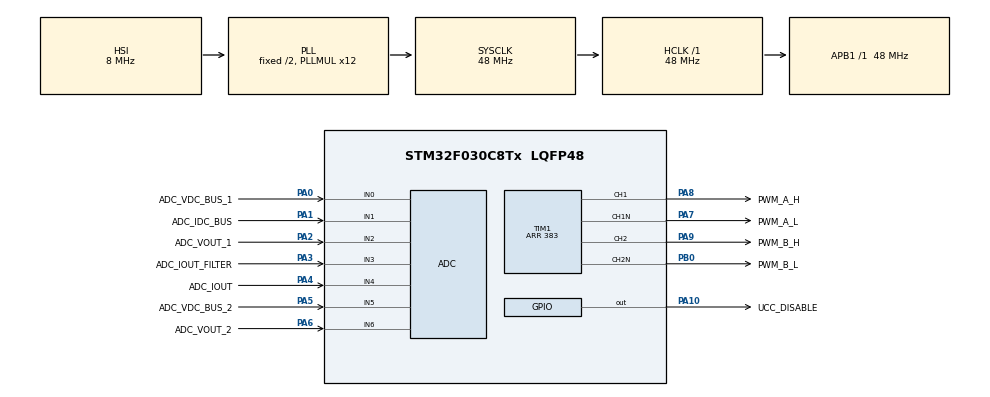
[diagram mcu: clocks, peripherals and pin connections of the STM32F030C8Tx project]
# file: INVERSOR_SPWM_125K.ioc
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ADC.SamplingTime=ADC_SAMPLETIME_28CYCLES_5
Mcu.Family=STM32F0
Mcu.Name=STM32F030C8Tx
Mcu.Package=LQFP48
NVIC.TIM1_BRK_UP_TRG_COM_IRQn=true\:0\:0\:false\:false\:true\:true\:true\:true
PA0.GPIO_Label=ADC_VDC_BUS_1
PA0.Mode=IN0
PA0.Signal=ADC_IN0
PA1.GPIO_Label=ADC_IDC_BUS 
PA1.Mode=IN1
PA1.Signal=ADC_IN1
PA10.GPIO_Label=UCC_DISABLE
PA10.GPIO_ModeDefaultOutputPP=GPIO_MODE_OUTPUT_PP
PA10.GPIO_PuPd=GPIO_NOPULL
PA10.PinState=GPIO_PIN_SET
PA10.Signal=GPIO_Output
PA13.Mode=Serial_Wire
PA13.Signal=SYS_SWDIO
PA14.Mode=Serial_Wire
PA14.Signal=SYS_SWCLK
PA2.GPIO_Label=ADC_VOUT_1
PA2.Mode=IN2
PA2.Signal=ADC_IN2
PA3.GPIO_Label=ADC_IOUT_FILTER
PA3.Mode=IN3
PA3.Signal=ADC_IN3
PA4.GPIO_Label=ADC_IOUT
PA4.Mode=IN4
PA4.Signal=ADC_IN4
PA5.GPIO_Label=ADC_VDC_BUS_2
PA5.Mode=IN5
PA5.Signal=ADC_IN5
PA6.GPIO_Label=ADC_VOUT_2
PA6.Mode=IN6
PA6.Signal=ADC_IN6
PA7.GPIO_Label=PWM_A_L
PA7.GPIO_Speed=GPIO_SPEED_FREQ_HIGH
PA7.Mode=PWM Generation1 CH1 CH1N
PA7.Signal=TIM1_CH1N
PA8.GPIO_Label=PWM_A_H
PA8.GPIO_Speed=GPIO_SPEED_FREQ_HIGH
PA8.Signal=S_TIM1_CH1
PA9.GPIO_Label=PWM_B_H
PA9.GPIO_Speed=GPIO_SPEED_FREQ_HIGH
PA9.Signal=S_TIM1_CH2
PB0.GPIO_Label=PWM_B_L
PB0.GPIO_Speed=GPIO_SPEED_FREQ_HIGH
PB0.Mode=PWM Generation2 CH2 CH2N
PB0.Signal=TIM1_CH2N
ProjectManager.HeapSize=0x200
ProjectManager.StackSize=0x400
ProjectManager.TargetToolchain=CMake
RCC.AHBFreq_Value=48000000
RCC.APB1Freq_Value=48000000
RCC.APB1TimFreq_Value=48000000
RCC.HCLKFreq_Value=48000000
RCC.PLLMUL=RCC_PLL_MUL12
RCC.SYSCLKFreq_VALUE=48000000
RCC.SYSCLKSource=RCC_SYSCLKSOURCE_PLLCLK
SH.S_TIM1_CH1.0=TIM1_CH1,PWM Generation1 CH1 CH1N
SH.S_TIM1_CH2.0=TIM1_CH2,PWM Generation2 CH2 CH2N
TIM1.AutoReloadPreload=TIM_AUTORELOAD_PRELOAD_ENABLE
TIM1.AutomaticOutput=TIM_AUTOMATICOUTPUT_ENABLE
TIM1.Channel-PWM\ Generation1\ CH1\ CH1N=TIM_CHANNEL_1
TIM1.Channel-PWM\ Generation2\ CH2\ CH2N=TIM_CHANNEL_2
TIM1.DeadTime=10
TIM1.Period=383
TIM1.Pulse-PWM\ Generation1\ CH1\ CH1N=192
TIM1.Pulse-PWM\ Generation2\ CH2\ CH2N=192
VP_TIM1_VS_ClockSourceINT.Mode=Internal
board=custom

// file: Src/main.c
/* USER CODE BEGIN Header */
/**
  ******************************************************************************
  * @file           : main.c
  * @brief          : Main program body
  ******************************************************************************
  * @attention
  *
  * Copyright (c) 2026 STMicroelectronics.
  * All rights reserved.
  *
  * This software is licensed under terms that can be found in the LICENSE file
  * in the root directory of this software component.
  * If no LICENSE file comes with this software, it is provided AS-IS.
  *
  ******************************************************************************
  */
/* USER CODE END Header */
#include "main.h"
#include "adc.h"
#include "tim.h"
#include "gpio.h"

/* USER CODE BEGIN Includes */
#include "spwm_inverter.h"

/* USER CODE END Includes */

/* USER CODE BEGIN PD */
#define SPWM_MODULATION_PERMILLE       800U

/* USER CODE END PD */

void SystemClock_Config(void);

int main(void)
{

  /* MCU Configuration--------------------------------------------------------*/

  /* Reset of all peripherals, Initializes the Flash interface and the Systick. */
  HAL_Init();

  /* Configure the system clock */
  SystemClock_Config();

  /* Initialize all configured peripherals */
  MX_GPIO_Init();
  MX_TIM1_Init();
  MX_ADC_Init();
  /* USER CODE BEGIN 2 */
  SPWM_Inverter_Init();
  SPWM_Inverter_SetModulationPermille(SPWM_MODULATION_PERMILLE);
  if (SPWM_Inverter_Start() != HAL_OK)
  {
    Error_Handler();
  }
  /* Validate PWM pins with a scope before calling SPWM_Inverter_EnablePowerStage(). */

  /* USER CODE END 2 */

  /* Infinite loop */
  while (1)
  {

  }
}

void SystemClock_Config(void)
{
  RCC_OscInitTypeDef RCC_OscInitStruct = {0};
  RCC_ClkInitTypeDef RCC_ClkInitStruct = {0};

  /** Initializes the RCC Oscillators according to the specified parameters
  * in the RCC_OscInitTypeDef structure.
  */
  RCC_OscInitStruct.OscillatorType = RCC_OSCILLATORTYPE_HSI|RCC_OSCILLATORTYPE_HSI14;
  RCC_OscInitStruct.HSIState = RCC_HSI_ON;
  RCC_OscInitStruct.HSI14State = RCC_HSI14_ON;
  RCC_OscInitStruct.HSICalibrationValue = RCC_HSICALIBRATION_DEFAULT;
  RCC_OscInitStruct.HSI14CalibrationValue = 16;
  RCC_OscInitStruct.PLL.PLLState = RCC_PLL_ON;
  RCC_OscInitStruct.PLL.PLLSource = RCC_PLLSOURCE_HSI;
  RCC_OscInitStruct.PLL.PLLMUL = RCC_PLL_MUL12;
  RCC_OscInitStruct.PLL.PREDIV = RCC_PREDIV_DIV1;
  if (HAL_RCC_OscConfig(&RCC_OscInitStruct) != HAL_OK)
  {
    Error_Handler();
  }

  /** Initializes the CPU, AHB and APB buses clocks
  */
  RCC_ClkInitStruct.ClockType = RCC_CLOCKTYPE_HCLK|RCC_CLOCKTYPE_SYSCLK
                              |RCC_CLOCKTYPE_PCLK1;
  RCC_ClkInitStruct.SYSCLKSource = RCC_SYSCLKSOURCE_PLLCLK;
  RCC_ClkInitStruct.AHBCLKDivider = RCC_SYSCLK_DIV1;
  RCC_ClkInitStruct.APB1CLKDivider = RCC_HCLK_DIV1;

  if (HAL_RCC_ClockConfig(&RCC_ClkInitStruct, FLASH_LATENCY_1) != HAL_OK)
  {
    Error_Handler();
  }
}

void Error_Handler(void)
{
  __disable_irq();
  while (1)
  {
  }
}
